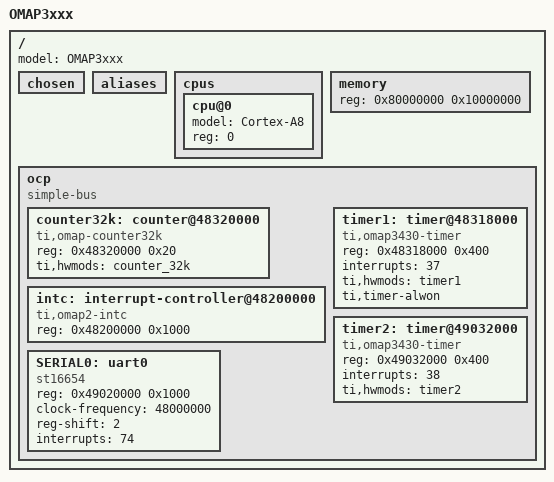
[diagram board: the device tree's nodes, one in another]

/ {
	#address-cells = <1>;
	#size-cells = <1>;
	model = "OMAP3xxx";
		
	chosen { };
	aliases { };

	cpus {
		#address-cells = <1>;
		#size-cells = <0>;

		cpu@0 {
			device_type = "cpu";
			model = "Cortex-A8";
			reg = <0>;
		};
	};

	memory {
		device_type = "memory"; 
		reg = <0x80000000 0x10000000>; /* 256 MB */
	};

	/*
	 * XXX: Use a flat representation of the OMAP3 interconnect.
	 * The real OMAP interconnect network is quite complex.
	 * Since that will not bring real advantage to represent that in DT for
	 * the moment, just use a fake OCP bus entry to represent the whole bus
	 * hierarchy.
	 */
	ocp {
		#address-cells = <1>;
		#size-cells = <1>;
		compatible = "simple-bus";

		counter32k: counter@48320000 {
			compatible = "ti,omap-counter32k";
			reg = <0x48320000 0x20>;
			ti,hwmods = "counter_32k";
		};

		intc: interrupt-controller@48200000 {
			device_type = "pic";
			compatible = "ti,omap2-intc";
			reg = <0x48200000 0x1000>;
		};

		timer1: timer@48318000 {
			compatible = "ti,omap3430-timer";
			reg = <0x48318000 0x400>;
			interrupts = <37>;
			ti,hwmods = "timer1";
			ti,timer-alwon;
		};

		timer2: timer@49032000 {
			compatible = "ti,omap3430-timer";
			reg = <0x49032000 0x400>;
			interrupts = <38>;
			ti,hwmods = "timer2";
		};

		SERIAL0: uart0 {
			compatible = "st16654";
			reg = <0x49020000 0x1000>;
			clock-frequency = <48000000>;
			reg-shift = <2>;
			interrupts = <74>;
		};
	};
};

